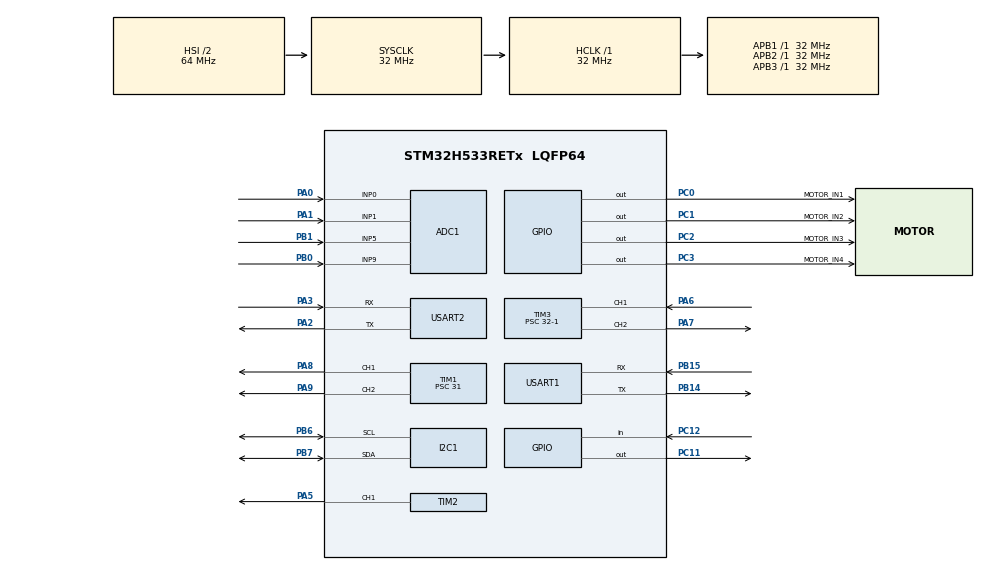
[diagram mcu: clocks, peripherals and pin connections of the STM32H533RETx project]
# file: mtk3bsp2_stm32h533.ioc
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ADC1.Channel-0\#ChannelRegularConversion=ADC_CHANNEL_0
ADC1.MonitoredBy-0\#ChannelRegularConversion=__NULL
ADC1.NbrOfConversionFlag=1
ADC1.OffsetNumber-0\#ChannelRegularConversion=ADC_OFFSET_NONE
ADC1.Rank-0\#ChannelRegularConversion=1
ADC1.SamplingTime-0\#ChannelRegularConversion=ADC_SAMPLETIME_2CYCLES_5
ADC1.master=1
BOOTPATH.BootPathName=LEGACY
BOOTPATH.UserSelectedBootPath=LEGACY
CORTEX_M33_NS.Number-Cortex_Memory_Protection_Unit_Region0_OTP_RO_AREAS_Settings=MPU_REGION_NUMBER0
CORTEX_M33_NS.default_mode_Activation=1
CORTEX_M33_NS.userName=CORTEX_M33
I2C1.Timing=0x00707CBB
Mcu.Family=STM32H5
Mcu.Name=STM32H533RETx
Mcu.Package=LQFP64
NVIC.ADC1_IRQn=true\:7\:0\:true\:false\:true\:true\:true\:true
NVIC.I2C1_ER_IRQn=true\:7\:0\:true\:false\:true\:true\:true\:true
NVIC.I2C1_EV_IRQn=true\:7\:0\:true\:false\:true\:true\:true\:true
NVIC.PriorityGroup=NVIC_PRIORITYGROUP_4
NVIC.TIM3_IRQn=true\:0\:0\:false\:false\:true\:true\:true\:true
NVIC.USART1_IRQn=true\:0\:0\:false\:false\:true\:true\:true\:true
NVIC.USART2_IRQn=true\:0\:0\:false\:false\:true\:true\:true\:true
PA0.Signal=ADCx_INP0
PA1.Signal=ADCx_INP1
PA13(JTMS/SWDIO).GPIO_Label=SWDIO
PA13(JTMS/SWDIO).Signal=DEBUG_JTMS-SWDIO
PA14(JTCK/SWCLK).GPIO_Label=SWCLK
PA14(JTCK/SWCLK).Signal=DEBUG_JTCK-SWCLK
PA15(JTDI).GPIO_Label=JTDI
PA15(JTDI).Signal=DEBUG_JTDI
PA2.Mode=Asynchronous
PA2.Signal=USART2_TX
PA3.Mode=Asynchronous
PA3.Signal=USART2_RX
PA5.Signal=S_TIM2_CH1
PA6.Signal=S_TIM3_CH1
PA7.Signal=S_TIM3_CH2
PA8.Signal=S_TIM1_CH1
PA9.Signal=S_TIM1_CH2
PB0.Signal=ADCx_INP9
PB1.Signal=ADCx_INP5
PB14.Mode=Asynchronous
PB14.Signal=USART1_TX
PB15.Mode=Asynchronous
PB15.Signal=USART1_RX
PB3(JTDO/TRACESWO).GPIO_Label=SWO
PB3(JTDO/TRACESWO).Signal=DEBUG_JTDO-SWO
PB6.Mode=I2C
PB6.Signal=I2C1_SCL
PB7.Mode=I2C
PB7.Signal=I2C1_SDA
PC0.GPIO_Label=MOTOR_IN1
PC0.Signal=GPIO_Output
PC1.GPIO_Label=MOTOR_IN2
PC1.Signal=GPIO_Output
PC11.Signal=GPIO_Output
PC12.Signal=GPIO_Input
PC2.GPIO_Label=MOTOR_IN3
PC2.Signal=GPIO_Output
PC3.GPIO_Label=MOTOR_IN4
PC3.Signal=GPIO_Output
ProjectManager.HeapSize=0x200
ProjectManager.StackSize=0x400
ProjectManager.TargetToolchain=STM32CubeIDE
RCC.ADCFreq_Value=32000000
RCC.AHBFreq_Value=32000000
RCC.APB1Freq_Value=32000000
RCC.APB1TimFreq_Value=32000000
RCC.APB2Freq_Value=32000000
RCC.APB2TimFreq_Value=32000000
RCC.APB3Freq_Value=32000000
RCC.CSI_VALUE=4000000
RCC.CortexFreq_Value=32000000
RCC.EPOD_VALUE=4000000
RCC.HCLKFreq_Value=32000000
RCC.HSE_VALUE=25000000
RCC.HSI48_VALUE=48000000
RCC.HSI_VALUE=64000000
RCC.LSE_VALUE=32768
RCC.LSIRC_VALUE=32000
RCC.SYSCLKFreq_VALUE=32000000
RCC.USBFreq_Value=48000000
RCC.VCOOutputFreq_Value=516000000
SH.ADCx_INP0.0=ADC1_INP0,IN0-Single-Ended
SH.ADCx_INP1.0=ADC1_INP1,IN1-Single-Ended
SH.ADCx_INP5.0=ADC1_INP5,IN5-Single-Ended
SH.ADCx_INP9.0=ADC1_INP9,IN9-Single-Ended
SH.S_TIM1_CH1.0=TIM1_CH1,PWM Generation1 CH1
SH.S_TIM1_CH2.0=TIM1_CH2,PWM Generation2 CH2
SH.S_TIM2_CH1.0=TIM2_CH1,PWM Generation1 CH1
SH.S_TIM3_CH1.0=TIM3_CH1,Input_Capture1_from_TI1
SH.S_TIM3_CH2.0=TIM3_CH2,PWM Generation2 CH2
TIM1.Channel-PWM\ Generation1\ CH1=TIM_CHANNEL_1
TIM1.Channel-PWM\ Generation2\ CH2=TIM_CHANNEL_2
TIM1.PeriodNoDither=999
TIM1.Prescaler=31
TIM2.Channel-PWM\ Generation1\ CH1=TIM_CHANNEL_1
TIM2.PeriodNoDither=19999
TIM2.Prescaler=31
TIM3.Channel-Input_Capture1_from_TI1=TIM_CHANNEL_1
TIM3.Channel-PWM\ Generation2\ CH2=TIM_CHANNEL_2
TIM3.PeriodNoDither=50000-1
TIM3.Prescaler=32-1
USART1.VirtualMode-Asynchronous=VM_ASYNC
USART2.VirtualMode-Asynchronous=VM_ASYNC
VP_BOOTPATH_VS_BOOTPATH.Mode=BP_Activate
VP_CORTEX_M33_NS_VS_Hclk.Mode=Hclk_Mode
VP_ICACHE_VS_ICACHE.Mode=DirectMappedCache
VP_MEMORYMAP_VS_MEMORYMAP.Mode=CurAppReg
VP_PWR_VS_LPOM.Mode=PowerOptimisation
VP_PWR_VS_SECSignals.Mode=Security/Privilege
VP_TIM1_VS_ClockSourceINT.Mode=Internal
VP_TIM2_VS_ClockSourceINT.Mode=Internal
VP_TIM3_VS_ClockSourceINT.Mode=Internal
board=NUCLEO-H533RE

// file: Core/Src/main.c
/* USER CODE BEGIN Header */
/**
  ******************************************************************************
  * @file           : main.c
  * @brief          : Main program body
  ******************************************************************************
  * @attention
  *
  * Copyright (c) 2026 STMicroelectronics.
  * All rights reserved.
  *
  * This software is licensed under terms that can be found in the LICENSE file
  * in the root directory of this software component.
  * If no LICENSE file comes with this software, it is provided AS-IS.
  *
  ******************************************************************************
  */
/* USER CODE END Header */
#include "main.h"

ADC_HandleTypeDef hadc1;

I2C_HandleTypeDef hi2c1;

TIM_HandleTypeDef htim1;
TIM_HandleTypeDef htim2;
TIM_HandleTypeDef htim3;

UART_HandleTypeDef huart1;
UART_HandleTypeDef huart2;

void SystemClock_Config(void);
static void MPU_Config(void);
static void MX_GPIO_Init(void);
static void MX_ICACHE_Init(void);
static void MX_USART2_UART_Init(void);
static void MX_ADC1_Init(void);
static void MX_I2C1_Init(void);
static void MX_TIM3_Init(void);
static void MX_USART1_UART_Init(void);
static void MX_TIM1_Init(void);
static void MX_TIM2_Init(void);

int main(void)
{

  /* MCU Configuration--------------------------------------------------------*/

  /* MPU Configuration--------------------------------------------------------*/
  MPU_Config();

  /* Reset of all peripherals, Initializes the Flash interface and the Systick. */
  HAL_Init();

  /* Configure the system clock */
  SystemClock_Config();

  /* Initialize all configured peripherals */
  MX_GPIO_Init();
  MX_ICACHE_Init();
  MX_USART2_UART_Init();
  MX_ADC1_Init();
  MX_I2C1_Init();
  MX_TIM3_Init();
  MX_USART1_UART_Init();
  MX_TIM1_Init();
  MX_TIM2_Init();
  /* USER CODE BEGIN 2 */
  void knl_start_mtkernel(void);
  knl_start_mtkernel();
  /* USER CODE END 2 */

  /* Infinite loop */
  while (1)
  {

  }
}

void SystemClock_Config(void)
{
  RCC_OscInitTypeDef RCC_OscInitStruct = {0};
  RCC_ClkInitTypeDef RCC_ClkInitStruct = {0};

  /** Configure the main internal regulator output voltage
  */
  __HAL_PWR_VOLTAGESCALING_CONFIG(PWR_REGULATOR_VOLTAGE_SCALE3);

  while(!__HAL_PWR_GET_FLAG(PWR_FLAG_VOSRDY)) {}

  /** Initializes the RCC Oscillators according to the specified parameters
  * in the RCC_OscInitTypeDef structure.
  */
  RCC_OscInitStruct.OscillatorType = RCC_OSCILLATORTYPE_HSI;
  RCC_OscInitStruct.HSIState = RCC_HSI_ON;
  RCC_OscInitStruct.HSIDiv = RCC_HSI_DIV2;
  RCC_OscInitStruct.HSICalibrationValue = RCC_HSICALIBRATION_DEFAULT;
  RCC_OscInitStruct.PLL.PLLState = RCC_PLL_NONE;
  if (HAL_RCC_OscConfig(&RCC_OscInitStruct) != HAL_OK)
  {
    Error_Handler();
  }

  /** Initializes the CPU, AHB and APB buses clocks
  */
  RCC_ClkInitStruct.ClockType = RCC_CLOCKTYPE_HCLK|RCC_CLOCKTYPE_SYSCLK
                              |RCC_CLOCKTYPE_PCLK1|RCC_CLOCKTYPE_PCLK2
                              |RCC_CLOCKTYPE_PCLK3;
  RCC_ClkInitStruct.SYSCLKSource = RCC_SYSCLKSOURCE_HSI;
  RCC_ClkInitStruct.AHBCLKDivider = RCC_SYSCLK_DIV1;
  RCC_ClkInitStruct.APB1CLKDivider = RCC_HCLK_DIV1;
  RCC_ClkInitStruct.APB2CLKDivider = RCC_HCLK_DIV1;
  RCC_ClkInitStruct.APB3CLKDivider = RCC_HCLK_DIV1;

  if (HAL_RCC_ClockConfig(&RCC_ClkInitStruct, FLASH_LATENCY_1) != HAL_OK)
  {
    Error_Handler();
  }

  /** Configure the programming delay
  */
  __HAL_FLASH_SET_PROGRAM_DELAY(FLASH_PROGRAMMING_DELAY_0);
}

static void MX_ADC1_Init(void)
{

  ADC_ChannelConfTypeDef sConfig = {0};

  /** Common config
  */
  hadc1.Instance = ADC1;
  hadc1.Init.ClockPrescaler = ADC_CLOCK_ASYNC_DIV1;
  hadc1.Init.Resolution = ADC_RESOLUTION_12B;
  hadc1.Init.DataAlign = ADC_DATAALIGN_RIGHT;
  hadc1.Init.ScanConvMode = ADC_SCAN_DISABLE;
  hadc1.Init.EOCSelection = ADC_EOC_SINGLE_CONV;
  hadc1.Init.LowPowerAutoWait = DISABLE;
  hadc1.Init.ContinuousConvMode = DISABLE;
  hadc1.Init.NbrOfConversion = 1;
  hadc1.Init.DiscontinuousConvMode = DISABLE;
  hadc1.Init.ExternalTrigConv = ADC_SOFTWARE_START;
  hadc1.Init.ExternalTrigConvEdge = ADC_EXTERNALTRIGCONVEDGE_NONE;
  hadc1.Init.DMAContinuousRequests = DISABLE;
  hadc1.Init.SamplingMode = ADC_SAMPLING_MODE_NORMAL;
  hadc1.Init.Overrun = ADC_OVR_DATA_PRESERVED;
  hadc1.Init.OversamplingMode = DISABLE;
  if (HAL_ADC_Init(&hadc1) != HAL_OK)
  {
    Error_Handler();
  }

  /** Configure Regular Channel
  */
  sConfig.Channel = ADC_CHANNEL_0;
  sConfig.Rank = ADC_REGULAR_RANK_1;
  sConfig.SamplingTime = ADC_SAMPLETIME_2CYCLES_5;
  sConfig.SingleDiff = ADC_SINGLE_ENDED;
  sConfig.OffsetNumber = ADC_OFFSET_NONE;
  sConfig.Offset = 0;
  if (HAL_ADC_ConfigChannel(&hadc1, &sConfig) != HAL_OK)
  {
    Error_Handler();
  }

}

static void MX_I2C1_Init(void)
{

  hi2c1.Instance = I2C1;
  hi2c1.Init.Timing = 0x00707CBB;
  hi2c1.Init.OwnAddress1 = 0;
  hi2c1.Init.AddressingMode = I2C_ADDRESSINGMODE_7BIT;
  hi2c1.Init.DualAddressMode = I2C_DUALADDRESS_DISABLE;
  hi2c1.Init.OwnAddress2 = 0;
  hi2c1.Init.OwnAddress2Masks = I2C_OA2_NOMASK;
  hi2c1.Init.GeneralCallMode = I2C_GENERALCALL_DISABLE;
  hi2c1.Init.NoStretchMode = I2C_NOSTRETCH_DISABLE;
  if (HAL_I2C_Init(&hi2c1) != HAL_OK)
  {
    Error_Handler();
  }

  /** Configure Analogue filter
  */
  if (HAL_I2CEx_ConfigAnalogFilter(&hi2c1, I2C_ANALOGFILTER_ENABLE) != HAL_OK)
  {
    Error_Handler();
  }

  /** Configure Digital filter
  */
  if (HAL_I2CEx_ConfigDigitalFilter(&hi2c1, 0) != HAL_OK)
  {
    Error_Handler();
  }

}

static void MX_ICACHE_Init(void)
{

  /** Enable instruction cache in 1-way (direct mapped cache)
  */
  if (HAL_ICACHE_ConfigAssociativityMode(ICACHE_1WAY) != HAL_OK)
  {
    Error_Handler();
  }
  if (HAL_ICACHE_Enable() != HAL_OK)
  {
    Error_Handler();
  }

}

static void MX_TIM1_Init(void)
{

  TIM_ClockConfigTypeDef sClockSourceConfig = {0};
  TIM_MasterConfigTypeDef sMasterConfig = {0};
  TIM_OC_InitTypeDef sConfigOC = {0};
  TIM_BreakDeadTimeConfigTypeDef sBreakDeadTimeConfig = {0};

  htim1.Instance = TIM1;
  htim1.Init.Prescaler = 31;
  htim1.Init.CounterMode = TIM_COUNTERMODE_UP;
  htim1.Init.Period = 999;
  htim1.Init.ClockDivision = TIM_CLOCKDIVISION_DIV1;
  htim1.Init.RepetitionCounter = 0;
  htim1.Init.AutoReloadPreload = TIM_AUTORELOAD_PRELOAD_DISABLE;
  if (HAL_TIM_Base_Init(&htim1) != HAL_OK)
  {
    Error_Handler();
  }
  sClockSourceConfig.ClockSource = TIM_CLOCKSOURCE_INTERNAL;
  if (HAL_TIM_ConfigClockSource(&htim1, &sClockSourceConfig) != HAL_OK)
  {
    Error_Handler();
  }
  if (HAL_TIM_PWM_Init(&htim1) != HAL_OK)
  {
    Error_Handler();
  }
  sMasterConfig.MasterOutputTrigger = TIM_TRGO_RESET;
  sMasterConfig.MasterOutputTrigger2 = TIM_TRGO2_RESET;
  sMasterConfig.MasterSlaveMode = TIM_MASTERSLAVEMODE_DISABLE;
  if (HAL_TIMEx_MasterConfigSynchronization(&htim1, &sMasterConfig) != HAL_OK)
  {
    Error_Handler();
  }
  sConfigOC.OCMode = TIM_OCMODE_PWM1;
  sConfigOC.Pulse = 0;
  sConfigOC.OCPolarity = TIM_OCPOLARITY_HIGH;
  sConfigOC.OCNPolarity = TIM_OCNPOLARITY_HIGH;
  sConfigOC.OCFastMode = TIM_OCFAST_DISABLE;
  sConfigOC.OCIdleState = TIM_OCIDLESTATE_RESET;
  sConfigOC.OCNIdleState = TIM_OCNIDLESTATE_RESET;
  if (HAL_TIM_PWM_ConfigChannel(&htim1, &sConfigOC, TIM_CHANNEL_1) != HAL_OK)
  {
    Error_Handler();
  }
  if (HAL_TIM_PWM_ConfigChannel(&htim1, &sConfigOC, TIM_CHANNEL_2) != HAL_OK)
  {
    Error_Handler();
  }
  sBreakDeadTimeConfig.OffStateRunMode = TIM_OSSR_DISABLE;
  sBreakDeadTimeConfig.OffStateIDLEMode = TIM_OSSI_DISABLE;
  sBreakDeadTimeConfig.LockLevel = TIM_LOCKLEVEL_OFF;
  sBreakDeadTimeConfig.DeadTime = 0;
  sBreakDeadTimeConfig.BreakState = TIM_BREAK_DISABLE;
  sBreakDeadTimeConfig.BreakPolarity = TIM_BREAKPOLARITY_HIGH;
  sBreakDeadTimeConfig.BreakFilter = 0;
  sBreakDeadTimeConfig.BreakAFMode = TIM_BREAK_AFMODE_INPUT;
  sBreakDeadTimeConfig.Break2State = TIM_BREAK2_DISABLE;
  sBreakDeadTimeConfig.Break2Polarity = TIM_BREAK2POLARITY_HIGH;
  sBreakDeadTimeConfig.Break2Filter = 0;
  sBreakDeadTimeConfig.Break2AFMode = TIM_BREAK_AFMODE_INPUT;
  sBreakDeadTimeConfig.AutomaticOutput = TIM_AUTOMATICOUTPUT_DISABLE;
  if (HAL_TIMEx_ConfigBreakDeadTime(&htim1, &sBreakDeadTimeConfig) != HAL_OK)
  {
    Error_Handler();
  }
  HAL_TIM_MspPostInit(&htim1);

}

static void MX_TIM2_Init(void)
{

  TIM_ClockConfigTypeDef sClockSourceConfig = {0};
  TIM_MasterConfigTypeDef sMasterConfig = {0};
  TIM_OC_InitTypeDef sConfigOC = {0};

  htim2.Instance = TIM2;
  htim2.Init.Prescaler = 31;
  htim2.Init.CounterMode = TIM_COUNTERMODE_UP;
  htim2.Init.Period = 19999;
  htim2.Init.ClockDivision = TIM_CLOCKDIVISION_DIV1;
  htim2.Init.AutoReloadPreload = TIM_AUTORELOAD_PRELOAD_DISABLE;
  if (HAL_TIM_Base_Init(&htim2) != HAL_OK)
  {
    Error_Handler();
  }
  sClockSourceConfig.ClockSource = TIM_CLOCKSOURCE_INTERNAL;
  if (HAL_TIM_ConfigClockSource(&htim2, &sClockSourceConfig) != HAL_OK)
  {
    Error_Handler();
  }
  if (HAL_TIM_PWM_Init(&htim2) != HAL_OK)
  {
    Error_Handler();
  }
  sMasterConfig.MasterOutputTrigger = TIM_TRGO_RESET;
  sMasterConfig.MasterSlaveMode = TIM_MASTERSLAVEMODE_DISABLE;
  if (HAL_TIMEx_MasterConfigSynchronization(&htim2, &sMasterConfig) != HAL_OK)
  {
    Error_Handler();
  }
  sConfigOC.OCMode = TIM_OCMODE_PWM1;
  sConfigOC.Pulse = 0;
  sConfigOC.OCPolarity = TIM_OCPOLARITY_HIGH;
  sConfigOC.OCFastMode = TIM_OCFAST_DISABLE;
  if (HAL_TIM_PWM_ConfigChannel(&htim2, &sConfigOC, TIM_CHANNEL_1) != HAL_OK)
  {
    Error_Handler();
  }
  HAL_TIM_MspPostInit(&htim2);

}

static void MX_TIM3_Init(void)
{

  TIM_ClockConfigTypeDef sClockSourceConfig = {0};
  TIM_MasterConfigTypeDef sMasterConfig = {0};
  TIM_IC_InitTypeDef sConfigIC = {0};
  TIM_OC_InitTypeDef sConfigOC = {0};

  htim3.Instance = TIM3;
  htim3.Init.Prescaler = 32-1;
  htim3.Init.CounterMode = TIM_COUNTERMODE_UP;
  htim3.Init.Period = 49999;
  htim3.Init.ClockDivision = TIM_CLOCKDIVISION_DIV1;
  htim3.Init.AutoReloadPreload = TIM_AUTORELOAD_PRELOAD_DISABLE;
  if (HAL_TIM_Base_Init(&htim3) != HAL_OK)
  {
    Error_Handler();
  }
  sClockSourceConfig.ClockSource = TIM_CLOCKSOURCE_INTERNAL;
  if (HAL_TIM_ConfigClockSource(&htim3, &sClockSourceConfig) != HAL_OK)
  {
    Error_Handler();
  }
  if (HAL_TIM_IC_Init(&htim3) != HAL_OK)
  {
    Error_Handler();
  }
  if (HAL_TIM_PWM_Init(&htim3) != HAL_OK)
  {
    Error_Handler();
  }
  sMasterConfig.MasterOutputTrigger = TIM_TRGO_RESET;
  sMasterConfig.MasterSlaveMode = TIM_MASTERSLAVEMODE_DISABLE;
  if (HAL_TIMEx_MasterConfigSynchronization(&htim3, &sMasterConfig) != HAL_OK)
  {
    Error_Handler();
  }
  sConfigIC.ICPolarity = TIM_INPUTCHANNELPOLARITY_RISING;
  sConfigIC.ICSelection = TIM_ICSELECTION_DIRECTTI;
  sConfigIC.ICPrescaler = TIM_ICPSC_DIV1;
  sConfigIC.ICFilter = 0;
  if (HAL_TIM_IC_ConfigChannel(&htim3, &sConfigIC, TIM_CHANNEL_1) != HAL_OK)
  {
    Error_Handler();
  }
  sConfigOC.OCMode = TIM_OCMODE_PWM1;
  sConfigOC.Pulse = 0;
  sConfigOC.OCPolarity = TIM_OCPOLARITY_HIGH;
  sConfigOC.OCFastMode = TIM_OCFAST_DISABLE;
  if (HAL_TIM_PWM_ConfigChannel(&htim3, &sConfigOC, TIM_CHANNEL_2) != HAL_OK)
  {
    Error_Handler();
  }
  HAL_TIM_MspPostInit(&htim3);

}

static void MX_USART1_UART_Init(void)
{

  huart1.Instance = USART1;
  huart1.Init.BaudRate = 115200;
  huart1.Init.WordLength = UART_WORDLENGTH_8B;
  huart1.Init.StopBits = UART_STOPBITS_1;
  huart1.Init.Parity = UART_PARITY_NONE;
  huart1.Init.Mode = UART_MODE_TX_RX;
  huart1.Init.HwFlowCtl = UART_HWCONTROL_NONE;
  huart1.Init.OverSampling = UART_OVERSAMPLING_16;
  huart1.Init.OneBitSampling = UART_ONE_BIT_SAMPLE_DISABLE;
  huart1.Init.ClockPrescaler = UART_PRESCALER_DIV1;
  huart1.AdvancedInit.AdvFeatureInit = UART_ADVFEATURE_NO_INIT;
  if (HAL_UART_Init(&huart1) != HAL_OK)
  {
    Error_Handler();
  }
  if (HAL_UARTEx_SetTxFifoThreshold(&huart1, UART_TXFIFO_THRESHOLD_1_8) != HAL_OK)
  {
    Error_Handler();
  }
  if (HAL_UARTEx_SetRxFifoThreshold(&huart1, UART_RXFIFO_THRESHOLD_1_8) != HAL_OK)
  {
    Error_Handler();
  }
  if (HAL_UARTEx_DisableFifoMode(&huart1) != HAL_OK)
  {
    Error_Handler();
  }

}

static void MX_USART2_UART_Init(void)
{

  huart2.Instance = USART2;
  huart2.Init.BaudRate = 115200;
  huart2.Init.WordLength = UART_WORDLENGTH_8B;
  huart2.Init.StopBits = UART_STOPBITS_1;
  huart2.Init.Parity = UART_PARITY_NONE;
  huart2.Init.Mode = UART_MODE_TX_RX;
  huart2.Init.HwFlowCtl = UART_HWCONTROL_NONE;
  huart2.Init.OverSampling = UART_OVERSAMPLING_16;
  huart2.Init.OneBitSampling = UART_ONE_BIT_SAMPLE_DISABLE;
  huart2.Init.ClockPrescaler = UART_PRESCALER_DIV1;
  huart2.AdvancedInit.AdvFeatureInit = UART_ADVFEATURE_NO_INIT;
  if (HAL_UART_Init(&huart2) != HAL_OK)
  {
    Error_Handler();
  }
  if (HAL_UARTEx_SetTxFifoThreshold(&huart2, UART_TXFIFO_THRESHOLD_1_8) != HAL_OK)
  {
    Error_Handler();
  }
  if (HAL_UARTEx_SetRxFifoThreshold(&huart2, UART_RXFIFO_THRESHOLD_1_8) != HAL_OK)
  {
    Error_Handler();
  }
  if (HAL_UARTEx_DisableFifoMode(&huart2) != HAL_OK)
  {
    Error_Handler();
  }

}

static void MX_GPIO_Init(void)
{
  GPIO_InitTypeDef GPIO_InitStruct = {0};

  /* GPIO Ports Clock Enable */
  __HAL_RCC_GPIOC_CLK_ENABLE();
  __HAL_RCC_GPIOA_CLK_ENABLE();
  __HAL_RCC_GPIOB_CLK_ENABLE();

  /*Configure GPIO pin Output Level */
  HAL_GPIO_WritePin(GPIOC, MOTOR_IN1_Pin|MOTOR_IN2_Pin|MOTOR_IN3_Pin|MOTOR_IN4_Pin
                          |GPIO_PIN_11, GPIO_PIN_RESET);

  /*Configure GPIO pins : MOTOR_IN1_Pin MOTOR_IN2_Pin MOTOR_IN3_Pin MOTOR_IN4_Pin
                           PC11 */
  GPIO_InitStruct.Pin = MOTOR_IN1_Pin|MOTOR_IN2_Pin|MOTOR_IN3_Pin|MOTOR_IN4_Pin
                          |GPIO_PIN_11;
  GPIO_InitStruct.Mode = GPIO_MODE_OUTPUT_PP;
  GPIO_InitStruct.Pull = GPIO_NOPULL;
  GPIO_InitStruct.Speed = GPIO_SPEED_FREQ_LOW;
  HAL_GPIO_Init(GPIOC, &GPIO_InitStruct);

  /*Configure GPIO pin : PC12 */
  GPIO_InitStruct.Pin = GPIO_PIN_12;
  GPIO_InitStruct.Mode = GPIO_MODE_INPUT;
  GPIO_InitStruct.Pull = GPIO_NOPULL;
  HAL_GPIO_Init(GPIOC, &GPIO_InitStruct);

}

 /* MPU Configuration */

void MPU_Config(void)
{
  MPU_Region_InitTypeDef MPU_InitStruct = {0};
  MPU_Attributes_InitTypeDef MPU_AttributesInit = {0};

  /* Disables the MPU */
  HAL_MPU_Disable();

  /** Initializes and configures the Region 0 and the memory to be protected
  */
  MPU_InitStruct.Enable = MPU_REGION_ENABLE;
  MPU_InitStruct.Number = MPU_REGION_NUMBER0;
  MPU_InitStruct.BaseAddress = 0x08FFF000;
  MPU_InitStruct.LimitAddress = 0x08FFFFFF;
  MPU_InitStruct.AttributesIndex = MPU_ATTRIBUTES_NUMBER0;
  MPU_InitStruct.AccessPermission = MPU_REGION_ALL_RO;
  MPU_InitStruct.DisableExec = MPU_INSTRUCTION_ACCESS_DISABLE;
  MPU_InitStruct.IsShareable = MPU_ACCESS_NOT_SHAREABLE;

  HAL_MPU_ConfigRegion(&MPU_InitStruct);

  /** Initializes and configures the Attribute 0 and the memory to be protected
  */
  MPU_AttributesInit.Number = MPU_ATTRIBUTES_NUMBER0;
  MPU_AttributesInit.Attributes = INNER_OUTER(MPU_NOT_CACHEABLE);

  HAL_MPU_ConfigMemoryAttributes(&MPU_AttributesInit);
  /* Enables the MPU */
  HAL_MPU_Enable(MPU_PRIVILEGED_DEFAULT);

}

void Error_Handler(void)
{
  __disable_irq();
  while (1)
  {
  }
}
